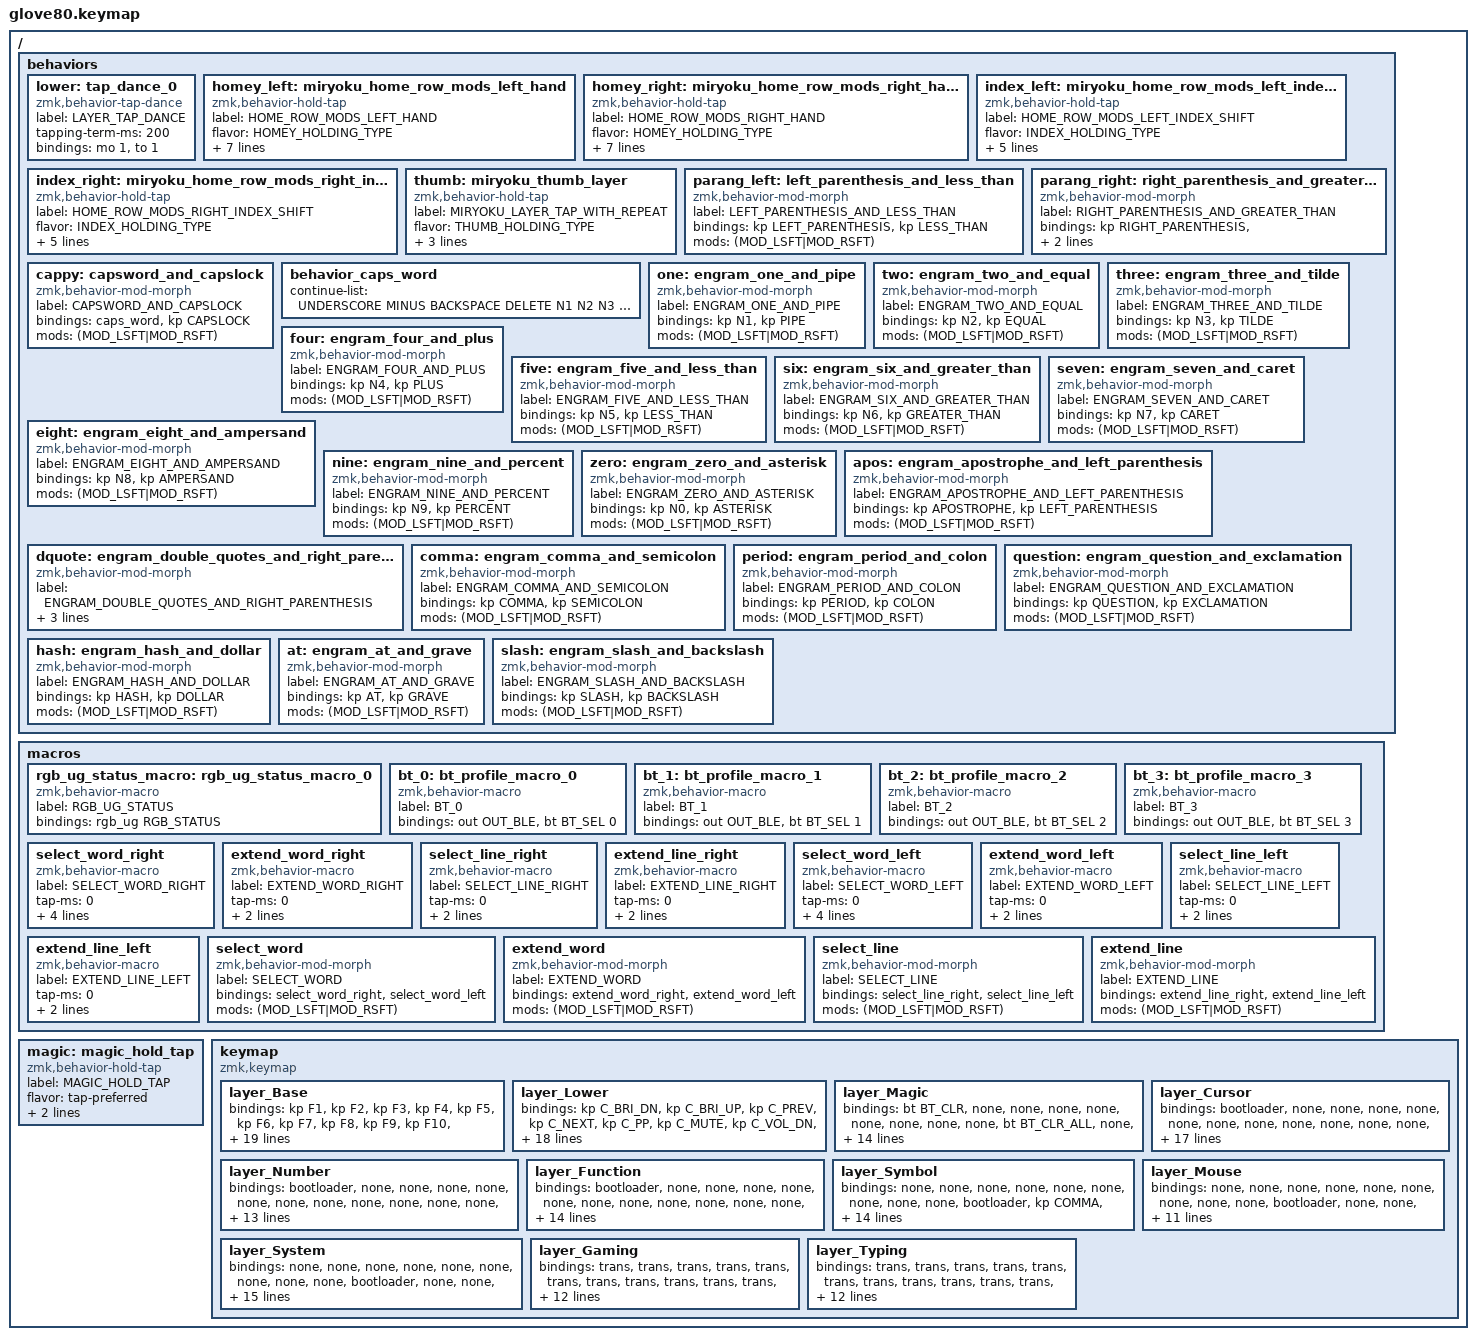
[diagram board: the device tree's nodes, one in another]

/*
 * Copyright (c) 2020 The ZMK Contributors
 * Copyright (c) 2022 Innaworks Development Limited, trading as MoErgo
 *
 * SPDX-License-Identifier: MIT
 */


/* THIS FILE WAS GENERATED BY GLOVE80 LAYOUT EDITOR
 *
 * This file was generated automatically. You may or may not want to
 * edit it directly.
 */

#include <behaviors.dtsi>
/* Include all behaviour includes needed by system behaviors/macros */
#include <dt-bindings/zmk/outputs.h>

/* Include behaviour includes needed by key binds - automatically generated */
#include <dt-bindings/zmk/keys.h>
#include <dt-bindings/zmk/bt.h>
#include <dt-bindings/zmk/rgb.h>
#include <dt-bindings/zmk/outputs.h>


/ {
    /* Glove80 system behavior & macros */
    behaviors {
        // For the "layer" key, it'd nice to be able to use it as either a shift or a toggle.
        // Configure it as a tap dance, so the first tap (or hold) is a &mo and the second tap is a &to
        lower: tap_dance_0 {
            compatible = "zmk,behavior-tap-dance";
            label = "LAYER_TAP_DANCE";
            #binding-cells = <0>;
            tapping-term-ms = <200>;
            bindings = <&mo 1>, <&to 1>;
        };
    };
};

/ {
    macros {
        rgb_ug_status_macro: rgb_ug_status_macro_0 {
            label = "RGB_UG_STATUS";
            compatible = "zmk,behavior-macro";
            #binding-cells = <0>;
            bindings
                = <&rgb_ug RGB_STATUS>;
        };

        bt_0: bt_profile_macro_0 {
            label = "BT_0";
            compatible = "zmk,behavior-macro";
            #binding-cells = <0>;
            bindings
                = <&out OUT_BLE>,
                  <&bt BT_SEL 0>;
        };

        bt_1: bt_profile_macro_1 {
            label = "BT_1";
            compatible = "zmk,behavior-macro";
            #binding-cells = <0>;
            bindings
                = <&out OUT_BLE>,
                  <&bt BT_SEL 1>;
        };

        bt_2: bt_profile_macro_2 {
            label = "BT_2";
            compatible = "zmk,behavior-macro";
            #binding-cells = <0>;
            bindings
                = <&out OUT_BLE>,
                  <&bt BT_SEL 2>;
        };

        bt_3: bt_profile_macro_3 {
            label = "BT_3";
            compatible = "zmk,behavior-macro";
            #binding-cells = <0>;
            bindings
                = <&out OUT_BLE>,
                  <&bt BT_SEL 3>;
        };
    };
};

/ {
    magic: magic_hold_tap {
        compatible = "zmk,behavior-hold-tap";
        label = "MAGIC_HOLD_TAP";
        #binding-cells = <2>;
        flavor = "tap-preferred";
        tapping-term-ms = <200>;
        bindings = <&mo>, <&rgb_ug_status_macro>;
    };
};

    /* Custom Defined Behaviors */
/ {
    //////////////////////////////////////////////////////////////////////
// NOTE: Use the `#define` settings below to customize this keymap! //
//////////////////////////////////////////////////////////////////////
// IMPORTANT: You need to set Firmware Version to "pr19.zephyr-3-2" //
// under Settings > Advanced Settings in the Glove80 Layout Editor  //
// if you want to use the `hold-trigger-on-release` feature in ZMK. //
//////////////////////////////////////////////////////////////////////
// CAUTION: PR19 firmware is not production quality; it has issues: //
// https://discord.com/channels/877392805654306816/1137025078979203142
//////////////////////////////////////////////////////////////////////
//
// Sunaku's Layout WIP featuring Engram(mer) layout and Miryoku system
// - https://sunaku.github.io/moergo-glove80-keyboard.html
// - https://discord.com/channels/877392805654306816/1111469812850380831
//

behaviors {

    //////////////////////////////////////////////////////////////////
    // Miryoku layers (thumb keys) and home row mods (non-thumb keys)
    // - https://sunaku.github.io/home-row-mods.html
    // - https://github.com/urob/zmk-config#timeless-homerow-mods
    //////////////////////////////////////////////////////////////////
    //
    // TYPING_STREAK_TERM defines how long you need to wait (milliseconds)
    // after typing before you can use home row mods again.  It prevents
    // unintended activation of home row mods when you're actively typing.
    //
    #define TYPING_STREAK_TERM 160 // global-quick-tap-ms
    //
    // KEY_REPEATING_TERM defines how much time you have left (milliseconds)
    // after tapping a key to hold it again in order to make it auto-repeat.
    //
    #define KEY_REPEATING_TERM 300 // "tap then hold" for key auto-repeat
    //
    // HOMEY_TAPPING_TERM defines how long you need to hold (milliseconds)
    // home row mod keys in order to send their modifiers to the computer
    // (i.e. "register" them) for mod-click mouse usage (e.g. Ctrl-Click).
    //
    #define HOMEY_TAPPING_TERM 260 // TAPPING_TERM + ALLOW_CROSSOVER_AFTER
    //
    // HOMEY_HOLDING_TYPE defines the flavor of ZMK hold-tap behavior to use
    // for the pinky, ring, and middle fingers (which are assigned to Super,
    // Alt, and Ctrl respectively in the Miryoku system) on home row keys.
    //
    #define HOMEY_HOLDING_TYPE "tap-preferred"
    //
    // INDEX_TAPPING_TERM defines how long you need to hold (milliseconds)
    // index finger keys in order to send their modifiers to the computer
    // (i.e. "register" them) for mod-click mouse usage (e.g. Shift-Click).
    //
    // CAUTION: You'll need to perform inward rolls from pinky->ring->middle
    // fingers toward the index fingers when activating multiple modifiers
    // because `hold-trigger-on-release` is disabled for the index fingers.
    // Otherwise, you may be surprised that the index fingers' modifier is
    // sent immediately without the rest of your multi-mod chord when you
    // perform outward rolls from your index fingers toward your pinkies.
    //
    #define INDEX_TAPPING_TERM 180
    //
    // INDEX_HOLDING_TYPE defines the flavor of ZMK hold-tap behavior to use
    // for index fingers (which Miryoku assigns to Shift) on home row keys.
    //
    // NOTE: The "tap-preferred" flavor of ZMK hold-tap for index finger keys
    // allows faster activation of the Shift modifier (without having to wait
    // for the modified key to be released as the "balanced" flavor requires).
    // Typing streaks and the `hold-trigger-on-release` setting are disabled
    // for the index fingers so as not to hinder their speed and dexterity.
    //
    #define INDEX_HOLDING_TYPE "tap-preferred"
    //
    // THUMB_TAPPING_TERM defines how long you need to hold (milliseconds)
    // a thumb key to activate a layer.  Shorter holds are treated as taps.
    //
    #define THUMB_TAPPING_TERM 200
    //
    // THUMB_HOLDING_TYPE defines the flavor of ZMK hold-tap behavior to use
    // for the thumbs (which are assigned to 6 layers in the Miryoku system).
    //
    // NOTE: The "balanced" flavor of ZMK hold-tap provides instant modifier
    // activation for the symbol layer (if the tapped symbol key is released
    // while the thumb layer key is still held down) for quicker programming.
    //
    #define THUMB_HOLDING_TYPE "balanced"
    //
    // Glove80 key positions index for positional hold-tap
    // - https://discord.com/channels/877392805654306816/937645688244826154/1066713913351221248
    // - https://media.discordapp.net/attachments/937645688244826154/1066713913133121556/image.png
    //
    // |------------------------|------------------------|
    // | LEFT_HAND_KEYS         |        RIGHT_HAND_KEYS |
    // |                        |                        |
    // |  0  1  2  3  4         |          5  6  7  8  9 |
    // | 10 11 12 13 14 15      |      16 17 18 19 20 21 |
    // | 22 23 24 25 26 27      |      28 29 30 31 32 33 |
    // | 34 35 36 37 38 39      |      40 41 42 43 44 45 |
    // | 46 47 48 49 50 51      |      58 59 60 61 62 63 |
    // | 64 65 66 67 68         |         75 76 77 78 79 |
    // |                69 52   |   57 74                |
    // |                 70 53  |  56 73                 |
    // |                  71 54 | 55 72                  |
    // |------------------------|------------------------|
    //
    #define LEFT_HAND_KEYS      \
          0  1  2  3  4         \
         10 11 12 13 14 15      \
         22 23 24 25 26 27      \
         34 35 36 37 38 39      \
         46 47 48 49 50 51      \
         64 65 66 67 68
    #define RIGHT_HAND_KEYS     \
                                           5  6  7  8  9 \
                                       16 17 18 19 20 21 \
                                       28 29 30 31 32 33 \
                                       40 41 42 43 44 45 \
                                       58 59 60 61 62 63 \
                                          75 76 77 78 79
    #define THUMB_KEYS          \
                        69 52       57 74                \
                         70 53     56 73                 \
                          71 54   55 72
    //
    // Home row mod-tap keys for all except index fingers
    //
    homey_left: miryoku_home_row_mods_left_hand {
        compatible = "zmk,behavior-hold-tap";
        label = "HOME_ROW_MODS_LEFT_HAND";
        flavor = HOMEY_HOLDING_TYPE;
        hold-trigger-key-positions = <RIGHT_HAND_KEYS THUMB_KEYS>;
        hold-trigger-on-release; // wait for other home row mods
        tapping-term-ms = <HOMEY_TAPPING_TERM>;
        quick-tap-ms = <TYPING_STREAK_TERM>;
        global-quick-tap; // with typing streak
        #binding-cells = <2>;
        bindings = <&kp>, <&kp>;
    };
    homey_right: miryoku_home_row_mods_right_hand {
        compatible = "zmk,behavior-hold-tap";
        label = "HOME_ROW_MODS_RIGHT_HAND";
        flavor = HOMEY_HOLDING_TYPE;
        hold-trigger-key-positions = <LEFT_HAND_KEYS THUMB_KEYS>;
        hold-trigger-on-release; // wait for other home row mods
        tapping-term-ms = <HOMEY_TAPPING_TERM>;
        quick-tap-ms = <TYPING_STREAK_TERM>;
        global-quick-tap; // with typing streak
        #binding-cells = <2>;
        bindings = <&kp>, <&kp>;
    };
    //
    // Special home row mod-tap keys for the index fingers
    //
    index_left: miryoku_home_row_mods_left_index_shift {
        compatible = "zmk,behavior-hold-tap";
        label = "HOME_ROW_MODS_LEFT_INDEX_SHIFT";
        flavor = INDEX_HOLDING_TYPE;
        hold-trigger-key-positions = <RIGHT_HAND_KEYS THUMB_KEYS>;
        //hold-trigger-on-release; // don't wait for other mods
        tapping-term-ms = <INDEX_TAPPING_TERM>;
        quick-tap-ms = <KEY_REPEATING_TERM>; // enable repeat
        //global-quick-tap; // no typing streak
        #binding-cells = <2>;
        bindings = <&kp>, <&kp>;
    };
    index_right: miryoku_home_row_mods_right_index_shift {
        compatible = "zmk,behavior-hold-tap";
        label = "HOME_ROW_MODS_RIGHT_INDEX_SHIFT";
        flavor = INDEX_HOLDING_TYPE;
        hold-trigger-key-positions = <LEFT_HAND_KEYS THUMB_KEYS>;
        //hold-trigger-on-release; // don't wait for other mods
        tapping-term-ms = <INDEX_TAPPING_TERM>;
        quick-tap-ms = <KEY_REPEATING_TERM>; // enable repeat
        //global-quick-tap; // no typing streak
        #binding-cells = <2>;
        bindings = <&kp>, <&kp>;
    };
    //
    // Thumb cluster hold-tap keys for Miryoku layers
    //
    thumb: miryoku_thumb_layer {
        compatible = "zmk,behavior-hold-tap";
        label = "MIRYOKU_LAYER_TAP_WITH_REPEAT";
        flavor = THUMB_HOLDING_TYPE;
        tapping-term-ms = <THUMB_TAPPING_TERM>;
        quick-tap-ms = <KEY_REPEATING_TERM>; // enable repeat
        //global-quick-tap; // no typing streak
        #binding-cells = <2>;
        bindings = <&mo>, <&kp>;
    };

    // Shift + LEFT_PARENTHESIS = LESS_THAN
    parang_left: left_parenthesis_and_less_than {
        compatible = "zmk,behavior-mod-morph";
        label = "LEFT_PARENTHESIS_AND_LESS_THAN";
        #binding-cells = <0>;
        bindings = <&kp LEFT_PARENTHESIS>, <&kp LESS_THAN>;
        mods = <(MOD_LSFT|MOD_RSFT)>;
    };

    // Shift + RIGHT_PARENTHESIS = GREATER_THAN
    parang_right: right_parenthesis_and_greater_than {
        compatible = "zmk,behavior-mod-morph";
        label = "RIGHT_PARENTHESIS_AND_GREATER_THAN";
        #binding-cells = <0>;
        bindings = <&kp RIGHT_PARENTHESIS>, <&kp GREATER_THAN>;
        mods = <(MOD_LSFT|MOD_RSFT)>;
    };

    // Shift + CapsWord = CapsLock
    cappy: capsword_and_capslock {
        compatible = "zmk,behavior-mod-morph";
        label = "CAPSWORD_AND_CAPSLOCK";
        #binding-cells = <0>;
        bindings = <&caps_word>, <&kp CAPSLOCK>;
        mods = <(MOD_LSFT|MOD_RSFT)>;
    };

    //
    // CapsWord - ported from Pascal Getreuer's extension for QMK
    // - https://zmk.dev/docs/behaviors/caps-word
    // - https://getreuer.info/posts/keyboards/caps-word/index.html
    //
    behavior_caps_word {
        continue-list = <UNDERSCORE MINUS BACKSPACE DELETE N1 N2 N3 N4 N5 N6 N7 N8 N9 N0>;
    };

    //
    // Custom shifted pairs for the Engram layout
    // - https://engram.dev/
    // - https://sunaku.github.io/engram-keyboard-layout.html
    //
    one: engram_one_and_pipe {
        compatible = "zmk,behavior-mod-morph";
        label = "ENGRAM_ONE_AND_PIPE";
        #binding-cells = <0>;
        bindings = <&kp N1>, <&kp PIPE>;
        mods = <(MOD_LSFT|MOD_RSFT)>;
    };
    two: engram_two_and_equal {
        compatible = "zmk,behavior-mod-morph";
        label = "ENGRAM_TWO_AND_EQUAL";
        #binding-cells = <0>;
        bindings = <&kp N2>, <&kp EQUAL>;
        mods = <(MOD_LSFT|MOD_RSFT)>;
    };
    three: engram_three_and_tilde {
        compatible = "zmk,behavior-mod-morph";
        label = "ENGRAM_THREE_AND_TILDE";
        #binding-cells = <0>;
        bindings = <&kp N3>, <&kp TILDE>;
        mods = <(MOD_LSFT|MOD_RSFT)>;
    };
    four: engram_four_and_plus {
        compatible = "zmk,behavior-mod-morph";
        label = "ENGRAM_FOUR_AND_PLUS";
        #binding-cells = <0>;
        bindings = <&kp N4>, <&kp PLUS>;
        mods = <(MOD_LSFT|MOD_RSFT)>;
    };
    five: engram_five_and_less_than {
        compatible = "zmk,behavior-mod-morph";
        label = "ENGRAM_FIVE_AND_LESS_THAN";
        #binding-cells = <0>;
        bindings = <&kp N5>, <&kp LESS_THAN>;
        mods = <(MOD_LSFT|MOD_RSFT)>;
    };
    six: engram_six_and_greater_than {
        compatible = "zmk,behavior-mod-morph";
        label = "ENGRAM_SIX_AND_GREATER_THAN";
        #binding-cells = <0>;
        bindings = <&kp N6>, <&kp GREATER_THAN>;
        mods = <(MOD_LSFT|MOD_RSFT)>;
    };
    seven: engram_seven_and_caret {
        compatible = "zmk,behavior-mod-morph";
        label = "ENGRAM_SEVEN_AND_CARET";
        #binding-cells = <0>;
        bindings = <&kp N7>, <&kp CARET>;
        mods = <(MOD_LSFT|MOD_RSFT)>;
    };
    eight: engram_eight_and_ampersand {
        compatible = "zmk,behavior-mod-morph";
        label = "ENGRAM_EIGHT_AND_AMPERSAND";
        #binding-cells = <0>;
        bindings = <&kp N8>, <&kp AMPERSAND>;
        mods = <(MOD_LSFT|MOD_RSFT)>;
    };
    nine: engram_nine_and_percent {
        compatible = "zmk,behavior-mod-morph";
        label = "ENGRAM_NINE_AND_PERCENT";
        #binding-cells = <0>;
        bindings = <&kp N9>, <&kp PERCENT>;
        mods = <(MOD_LSFT|MOD_RSFT)>;
    };
    zero: engram_zero_and_asterisk {
        compatible = "zmk,behavior-mod-morph";
        label = "ENGRAM_ZERO_AND_ASTERISK";
        #binding-cells = <0>;
        bindings = <&kp N0>, <&kp ASTERISK>;
        mods = <(MOD_LSFT|MOD_RSFT)>;
    };
    apos: engram_apostrophe_and_left_parenthesis {
        compatible = "zmk,behavior-mod-morph";
        label = "ENGRAM_APOSTROPHE_AND_LEFT_PARENTHESIS";
        #binding-cells = <0>;
        bindings = <&kp APOSTROPHE>, <&kp LEFT_PARENTHESIS>;
        mods = <(MOD_LSFT|MOD_RSFT)>;
    };
    dquote: engram_double_quotes_and_right_parenthesis {
        compatible = "zmk,behavior-mod-morph";
        label = "ENGRAM_DOUBLE_QUOTES_AND_RIGHT_PARENTHESIS";
        #binding-cells = <0>;
        bindings = <&kp DOUBLE_QUOTES>, <&kp RIGHT_PARENTHESIS>;
        mods = <(MOD_LSFT|MOD_RSFT)>;
    };
    comma: engram_comma_and_semicolon {
        compatible = "zmk,behavior-mod-morph";
        label = "ENGRAM_COMMA_AND_SEMICOLON";
        #binding-cells = <0>;
        bindings = <&kp COMMA>, <&kp SEMICOLON>;
        mods = <(MOD_LSFT|MOD_RSFT)>;
    };
    period: engram_period_and_colon {
        compatible = "zmk,behavior-mod-morph";
        label = "ENGRAM_PERIOD_AND_COLON";
        #binding-cells = <0>;
        bindings = <&kp PERIOD>, <&kp COLON>;
        mods = <(MOD_LSFT|MOD_RSFT)>;
    };
    question: engram_question_and_exclamation {
        compatible = "zmk,behavior-mod-morph";
        label = "ENGRAM_QUESTION_AND_EXCLAMATION";
        #binding-cells = <0>;
        bindings = <&kp QUESTION>, <&kp EXCLAMATION>;
        mods = <(MOD_LSFT|MOD_RSFT)>;
    };
    hash: engram_hash_and_dollar {
        compatible = "zmk,behavior-mod-morph";
        label = "ENGRAM_HASH_AND_DOLLAR";
        #binding-cells = <0>;
        bindings = <&kp HASH>, <&kp DOLLAR>;
        mods = <(MOD_LSFT|MOD_RSFT)>;
    };
    at: engram_at_and_grave {
        compatible = "zmk,behavior-mod-morph";
        label = "ENGRAM_AT_AND_GRAVE";
        #binding-cells = <0>;
        bindings = <&kp AT>, <&kp GRAVE>;
        mods = <(MOD_LSFT|MOD_RSFT)>;
    };
    slash: engram_slash_and_backslash {
        compatible = "zmk,behavior-mod-morph";
        label = "ENGRAM_SLASH_AND_BACKSLASH";
        #binding-cells = <0>;
        bindings = <&kp SLASH>, <&kp BACKSLASH>;
        mods = <(MOD_LSFT|MOD_RSFT)>;
    };

};

macros {

    //
    // Approximation of Pascal Getreuer's Select Word macro from QMK
    // - https://getreuer.info/posts/keyboards/select-word/index.html
    //
    select_word_right: select_word_right {
        compatible = "zmk,behavior-macro";
        label = "SELECT_WORD_RIGHT";
        #binding-cells = <0>;
        tap-ms = <0>;
        wait-ms = <0>;
        bindings
        = <&macro_tap &kp LC(RIGHT)>
        , <&macro_wait_time 1> // let cursor move to the next word!
        , <&macro_tap &kp LC(LEFT) &kp LC(LS(RIGHT))>
        ;
    };
    extend_word_right: extend_word_right {
        compatible = "zmk,behavior-macro";
        label = "EXTEND_WORD_RIGHT";
        #binding-cells = <0>;
        tap-ms = <0>;
        wait-ms = <0>;
        bindings
        = <&macro_tap &kp LC(LS(RIGHT))>
        ;
    };
    select_line_right: select_line_right {
        compatible = "zmk,behavior-macro";
        label = "SELECT_LINE_RIGHT";
        #binding-cells = <0>;
        tap-ms = <0>;
        wait-ms = <0>;
        bindings
        = <&macro_tap &kp HOME &kp LS(END)>
        ;
    };
    extend_line_right: extend_line_right {
        compatible = "zmk,behavior-macro";
        label = "EXTEND_LINE_RIGHT";
        #binding-cells = <0>;
        tap-ms = <0>;
        wait-ms = <0>;
        bindings
        = <&macro_tap &kp LS(DOWN) &kp LS(END)>
        ;
    };
    select_word_left: select_word_left {
        compatible = "zmk,behavior-macro";
        label = "SELECT_WORD_LEFT";
        #binding-cells = <0>;
        tap-ms = <0>;
        wait-ms = <0>;
        bindings
        /* = <&macro_tap &kp LC(RIGHT)> */
        = <&macro_tap &kp LC(LEFT)>
        , <&macro_wait_time 1> // let cursor move to the next word!
        , <&macro_tap &kp LC(RIGHT) &kp LC(LS(LEFT))>
        ;
    };
    extend_word_left: extend_word_left {
        compatible = "zmk,behavior-macro";
        label = "EXTEND_WORD_LEFT";
        #binding-cells = <0>;
        tap-ms = <0>;
        wait-ms = <0>;
        bindings
        = <&macro_tap &kp LC(LS(LEFT))>
        ;
    };
    select_line_left: select_line_left {
        compatible = "zmk,behavior-macro";
        label = "SELECT_LINE_LEFT";
        #binding-cells = <0>;
        tap-ms = <0>;
        wait-ms = <0>;
        bindings
        = <&macro_tap &kp END &kp LS(HOME)>
        ;
    };
    extend_line_left: extend_line_left {
        compatible = "zmk,behavior-macro";
        label = "EXTEND_LINE_LEFT";
        #binding-cells = <0>;
        tap-ms = <0>;
        wait-ms = <0>;
        bindings
        = <&macro_tap &kp LS(UP) &kp LS(HOME)>
        ;
    };
    select_word: select_word {
        compatible = "zmk,behavior-mod-morph";
        label = "SELECT_WORD";
        #binding-cells = <0>;
        bindings = <&select_word_right>, <&select_word_left>;
        mods = <(MOD_LSFT|MOD_RSFT)>;
    };
    extend_word: extend_word {
        compatible = "zmk,behavior-mod-morph";
        label = "EXTEND_WORD";
        #binding-cells = <0>;
        bindings = <&extend_word_right>, <&extend_word_left>;
        mods = <(MOD_LSFT|MOD_RSFT)>;
    };
    select_line: select_line {
        compatible = "zmk,behavior-mod-morph";
        label = "SELECT_LINE";
        #binding-cells = <0>;
        bindings = <&select_line_right>, <&select_line_left>;
        mods = <(MOD_LSFT|MOD_RSFT)>;
    };
    extend_line: extend_line {
        compatible = "zmk,behavior-mod-morph";
        label = "EXTEND_LINE";
        #binding-cells = <0>;
        bindings = <&extend_line_right>, <&extend_line_left>;
        mods = <(MOD_LSFT|MOD_RSFT)>;
    };

};
};

    /* Automatically generated keymap */
/ {
    keymap {
        compatible = "zmk,keymap";


        layer_Base {
            bindings = <
     &kp F1              &kp F2              &kp F3               &kp F4               &kp F5                                                                                                                            &kp F6                &kp F7               &kp F8               &kp F9     &kp F10
  &kp EQUAL              &kp N1              &kp N2               &kp N3               &kp N4     &kp N5                                                                                           &kp N6                &kp N7                &kp N8               &kp N9               &kp N0    &kp BSLH
  &kp GRAVE               &kp B  &homey_left RALT Y                &kp O                &kp U    &kp SQT                                                                                         &kp SEMI                 &kp L                 &kp D  &homey_right RALT W                &kp V       &kp Z
     &cappy  &homey_left LGUI C  &homey_left LALT I  &homey_left LCTRL E  &index_left LSHFT A  &kp COMMA                                                                                          &kp DOT  &index_right LSHFT H  &homey_right LCTRL T  &homey_right LALT S  &homey_right LGUI N       &kp Q
  &kp LSHFT               &kp G               &kp X                &kp J                &kp K  &kp MINUS        &thumb 5 ESC           &kp UP  &kp DOWN  &kp LEFT     &kp RIGHT  &thumb 8 ENTER  &kp FSLH                 &kp R                 &kp M                &kp F                &kp P   &kp RSHFT
 &magic 2 0            &kp HOME           &kp PG_UP            &kp PG_DN              &kp END             &thumb 3 BACKSPACE  &thumb 4 DELETE    &lower    &lower  &thumb 7 TAB  &thumb 6 SPACE                    &parang_left              &kp LBKT             &kp RBKT        &parang_right  &magic 2 0
            >;
        };

        layer_Lower {
            bindings = <
 &kp C_BRI_DN  &kp C_BRI_UP      &kp C_PREV      &kp C_NEXT         &kp C_PP                                                                                      &kp C_MUTE  &kp C_VOL_DN  &kp C_VOL_UP            &none  &kp PAUSE_BREAK
       &trans         &none           &none           &none            &none   &kp HOME                                                     &kp LEFT_PARENTHESIS  &kp KP_NUM  &kp KP_EQUAL  &kp KP_SLASH  &kp KP_MULTIPLY  &kp PRINTSCREEN
       &trans         &none           &none    &kp UP_ARROW            &none    &kp END                                                    &kp RIGHT_PARENTHESIS   &kp KP_N7     &kp KP_N8     &kp KP_N9     &kp KP_MINUS   &kp SCROLLLOCK
       &trans         &none  &kp LEFT_ARROW  &kp DOWN_ARROW  &kp RIGHT_ARROW  &kp PG_UP                                                              &kp PERCENT   &kp KP_N4     &kp KP_N5     &kp KP_N6      &kp KP_PLUS            &none
       &trans     &kp K_APP           &none         &kp F11          &kp F12  &kp PG_DN  &tog 5  &tog 9  &tog 10  &tog 10  &tog 9  &tog 8              &kp COMMA   &kp KP_N1     &kp KP_N2     &kp KP_N3     &kp KP_ENTER           &trans
   &magic 2 0      &kp CAPS         &kp INS         &kp F11          &kp F12             &tog 3  &tog 4    &to 0    &to 0  &tog 7  &tog 6                          &kp KP_N0     &kp KP_N0    &kp KP_DOT     &kp KP_ENTER           &trans
            >;
        };

        layer_Magic {
            bindings = <
  &bt BT_CLR            &none            &none            &none            &none                                                                                  &none   &none   &none   &none  &bt BT_CLR_ALL
       &none            &none            &none            &none            &none            &none                                                         &none   &none   &none   &none   &none           &none
       &none  &rgb_ug RGB_SPI  &rgb_ug RGB_SAI  &rgb_ug RGB_HUI  &rgb_ug RGB_BRI  &rgb_ug RGB_TOG                                                         &none   &none   &none   &none   &none           &none
 &bootloader  &rgb_ug RGB_SPD  &rgb_ug RGB_SAD  &rgb_ug RGB_HUD  &rgb_ug RGB_BRD  &rgb_ug RGB_EFF                                                         &none   &none   &none   &none   &none     &bootloader
  &sys_reset            &none            &none            &none            &none            &none   &bt_2   &bt_3         &none   &none   &none   &none   &none   &none   &none   &none   &none      &sys_reset
       &none            &none            &none            &none            &none                    &bt_0   &bt_1  &out OUT_USB   &none   &none   &none           &none   &none   &none   &none           &none
            >;
        };

        layer_Cursor {
            bindings = <
 &bootloader          &none      &none          &none          &none                                                                                           &none          &none          &none      &none      &none
       &none          &none      &none   &select_line   &extend_line  &kp LC(A)                                                                     &none      &none  &kp LS(LC(Z))  &kp LS(LC(Y))      &none      &none
   &kp LC(K)          &none   &kp RALT   &select_word   &extend_word  &kp LC(X)                                                                 &kp LC(X)   &kp BSPC      &kp LC(Z)      &kp LC(Y)    &kp DEL  &kp LC(K)
   &kp LC(L)       &kp LGUI   &kp LALT      &kp LCTRL      &kp LSHFT  &kp LC(C)                                                                 &kp LC(C)   &kp LEFT         &kp UP       &kp DOWN  &kp RIGHT  &kp LC(L)
   &kp LC(J)      &kp LC(H)  &kp LC(F)      &kp LC(Z)      &kp LC(Y)  &kp LC(V)   &to 0   &to 0   &to 0  &kp LC(L)  &extend_line  &extend_word  &kp LC(V)   &kp HOME      &kp PG_UP      &kp PG_DN    &kp END  &kp LC(J)
  &sys_reset  &kp LS(LC(G))  &kp LC(G)  &kp LS(LC(Z))  &kp LS(LC(Y))              &none   &to 0   &to 0  &kp LC(A)  &select_line  &select_word             &kp LC(F)  &kp LS(LC(G))      &kp LC(G)  &kp LC(H)    &kp INS
            >;
        };

        layer_Number {
            bindings = <
 &bootloader     &none     &none      &none      &none                                                                                &none     &none     &none      &none      &none
       &none     &none     &none      &none      &none   &none                                                         &kp TILDE  &kp CARET  &kp HASH  &kp DLLR     &kp AT   &kp EXCL
       &none     &none  &kp RALT      &none      &none   &none                                                         &kp PRCNT     &kp N7    &kp N8    &kp N9  &kp COLON      &kp K
  &kp KP_NUM  &kp LGUI  &kp LALT  &kp LCTRL  &kp LSHFT   &none                                                          &kp PLUS     &kp N4    &kp N5    &kp N6  &kp MINUS      &kp J
       &none     &none     &none      &none      &none   &none   &to 0   &to 0   &to 0     &kp LT   &kp GT  &kp EQUAL   &kp STAR     &kp N1    &kp N2    &kp N3   &kp FSLH  &kp LS(G)
  &sys_reset     &none     &none      &none      &none           &to 0   &none   &to 0  &kp COMMA  &kp DOT     &kp N0                &trans    &trans    &trans     &trans   &kp PIPE
            >;
        };

        layer_Function {
            bindings = <
 &bootloader     &none     &none      &none      &none                                                                                                    &none         &none         &none          &none           &none
       &none     &none     &none      &none      &none   &none                                                                  &kp C_MEDIA_HOME     &kp C_PLAY    &kp C_PREV    &kp C_NEXT     &kp C_STOP     &kp C_EJECT
       &none     &none  &kp RALT      &none      &none   &none                                                                         &kp K_WWW         &kp F7        &kp F8        &kp F9        &kp F10         &kp F13
    &kp CAPS  &kp LGUI  &kp LALT  &kp LCTRL  &kp LSHFT   &none                                                                        &kp K_CALC         &kp F4        &kp F5        &kp F6        &kp F11         &kp F14
       &none     &none     &none      &none      &none   &none   &none   &to 0   &to 0  &kp C_PREV    &kp C_NEXT      &kp C_PP    &kp C_AL_FILES         &kp F1        &kp F2        &kp F3        &kp F12         &kp F15
  &sys_reset     &none     &none      &none      &none           &to 0   &to 0   &to 0  &kp C_MUTE  &kp C_VOL_DN  &kp C_VOL_UP                    &kp C_BRI_MAX  &kp C_BRI_UP  &kp C_BRI_DN  &kp C_BRI_MIN  &kp C_BRI_AUTO
            >;
        };

        layer_Symbol {
            bindings = <
     &none      &none      &none      &none     &none                                                                                 &none      &none     &none     &none  &bootloader
 &kp COMMA   &kp LBKT   &kp LPAR   &kp RPAR  &kp RBKT   &kp SEMI                                                           &none      &none      &none     &none     &none        &none
 &kp TILDE   &kp LBRC    &kp DQT  &kp GRAVE  &kp RBRC  &kp QMARK                                                           &none      &none      &none  &kp RALT     &none        &none
  &kp HASH  &kp CARET  &kp EQUAL  &kp UNDER  &kp DLLR   &kp STAR                                                           &none  &kp LSHFT  &kp LCTRL  &kp LALT  &kp LGUI        &none
  &kp EXCL     &kp LT   &kp PIPE  &kp MINUS    &kp GT   &kp FSLH   &kp BSLH    &kp DOT  &kp STAR   &to 0   &to 0   &to 0   &none      &none      &none     &none     &none        &none
     &none  &kp COMMA   &kp AMPS   &kp PLUS  &kp SEMI             &kp PRCNT  &kp COLON    &kp AT   &to 0   &to 0   &none              &none      &none     &none     &none   &sys_reset
            >;
        };

        layer_Mouse {
            bindings = <
  &none   &none   &none   &none   &none                                                                      &none      &none     &none     &none  &bootloader
  &none   &none   &none   &none   &none   &none                                                   &none      &none      &none     &none     &none        &none
  &none   &none   &none   &none   &none   &none                                                   &none      &none      &none  &kp RALT     &none        &none
  &none   &none   &none   &none   &none   &none                                                   &none  &kp LSHFT  &kp LCTRL  &kp LALT  &kp LGUI        &none
  &none   &none   &none   &none   &none   &none   &none   &none   &none   &to 0   &to 0   &to 0   &none      &none      &none     &none     &none        &none
  &none   &none   &none   &none   &none           &none   &none   &none   &to 0   &none   &to 0              &none      &none     &none     &none   &sys_reset
            >;
        };

        layer_System {
            bindings = <
           &none            &none            &none            &none            &none                                                                                        &none      &none     &none     &none  &bootloader
           &none            &none            &none            &none            &none   &none                                                                     &none      &none      &none     &none     &none        &none
           &none            &none  &rgb_ug RGB_HUD  &rgb_ug RGB_HUI            &none   &none                                                                     &none      &none      &none  &kp RALT     &none        &none
 &rgb_ug RGB_TOG  &rgb_ug RGB_EFR  &rgb_ug RGB_BRD  &rgb_ug RGB_BRI  &rgb_ug RGB_EFF   &none                                                                     &none  &kp LSHFT  &kp LCTRL  &kp LALT  &kp LGUI        &none
           &none  &rgb_ug RGB_SPD  &rgb_ug RGB_SAD  &rgb_ug RGB_SAI  &rgb_ug RGB_SPI   &none  &kp K_LOCK  &kp C_SLEEP        &kp C_PWR   &to 0   &to 0   &none   &none      &none      &none     &none     &none        &none
           &none            &none            &none            &none            &none           &kp PSCRN     &kp SLCK  &kp PAUSE_BREAK   &to 0   &to 0   &to 0              &none      &none     &none     &none   &sys_reset
            >;
        };

        layer_Gaming {
            bindings = <
    &trans     &trans  &trans  &trans  &trans                                                                                    &trans  &trans     &trans   &trans    &trans
    &trans     &trans  &trans  &trans  &trans   &trans                                                                   &trans  &trans  &trans     &trans   &trans    &trans
 &kp MINUS  &kp GRAVE   &kp B   &kp N   &kp M  &kp SQT                                                                    &kp B   &kp N   &kp M  &kp COMMA  &kp DOT  &kp FSLH
     &kp T    &kp TAB   &kp Q   &kp W   &kp E    &kp R                                                                    &kp T   &kp Y   &kp U      &kp I    &kp O     &kp P
     &kp G  &kp LSHFT   &kp A   &kp S   &kp D    &kp F    &kp ESC   &kp RET         &kp LGUI  &kp BSPC  &kp DEL  &trans   &kp G   &kp H   &kp J      &kp K    &kp L  &kp SEMI
     &kp V  &kp LCTRL   &kp Z   &kp X   &kp C           &kp SPACE  &kp LALT  &kp PAUSE_BREAK     &to 0   &trans  &trans          &trans  &trans     &trans   &trans    &trans
            >;
        };

        layer_Typing {
            bindings = <
 &trans  &trans  &trans  &trans  &trans                                                                         &trans  &trans  &trans  &trans  &trans
 &trans  &trans  &trans  &trans  &trans  &trans                                                         &trans  &trans  &trans  &trans  &trans  &trans
 &trans  &trans   &kp Y  &trans  &trans  &trans                                                         &trans  &trans  &trans   &kp W  &trans  &trans
 &trans   &kp C   &kp I   &kp E   &kp A  &trans                                                         &trans   &kp H   &kp T   &kp S   &kp N  &trans
 &trans  &trans  &trans  &trans  &trans  &trans   &kp ESC   &trans  &trans  &trans   &trans    &kp RET  &trans  &trans  &trans  &trans  &trans  &trans
 &trans  &trans  &trans  &trans  &trans          &kp BSPC  &kp DEL   &to 0   &to 0  &kp TAB  &kp SPACE          &trans  &trans  &trans  &trans  &trans
            >;
        };

    };
};
